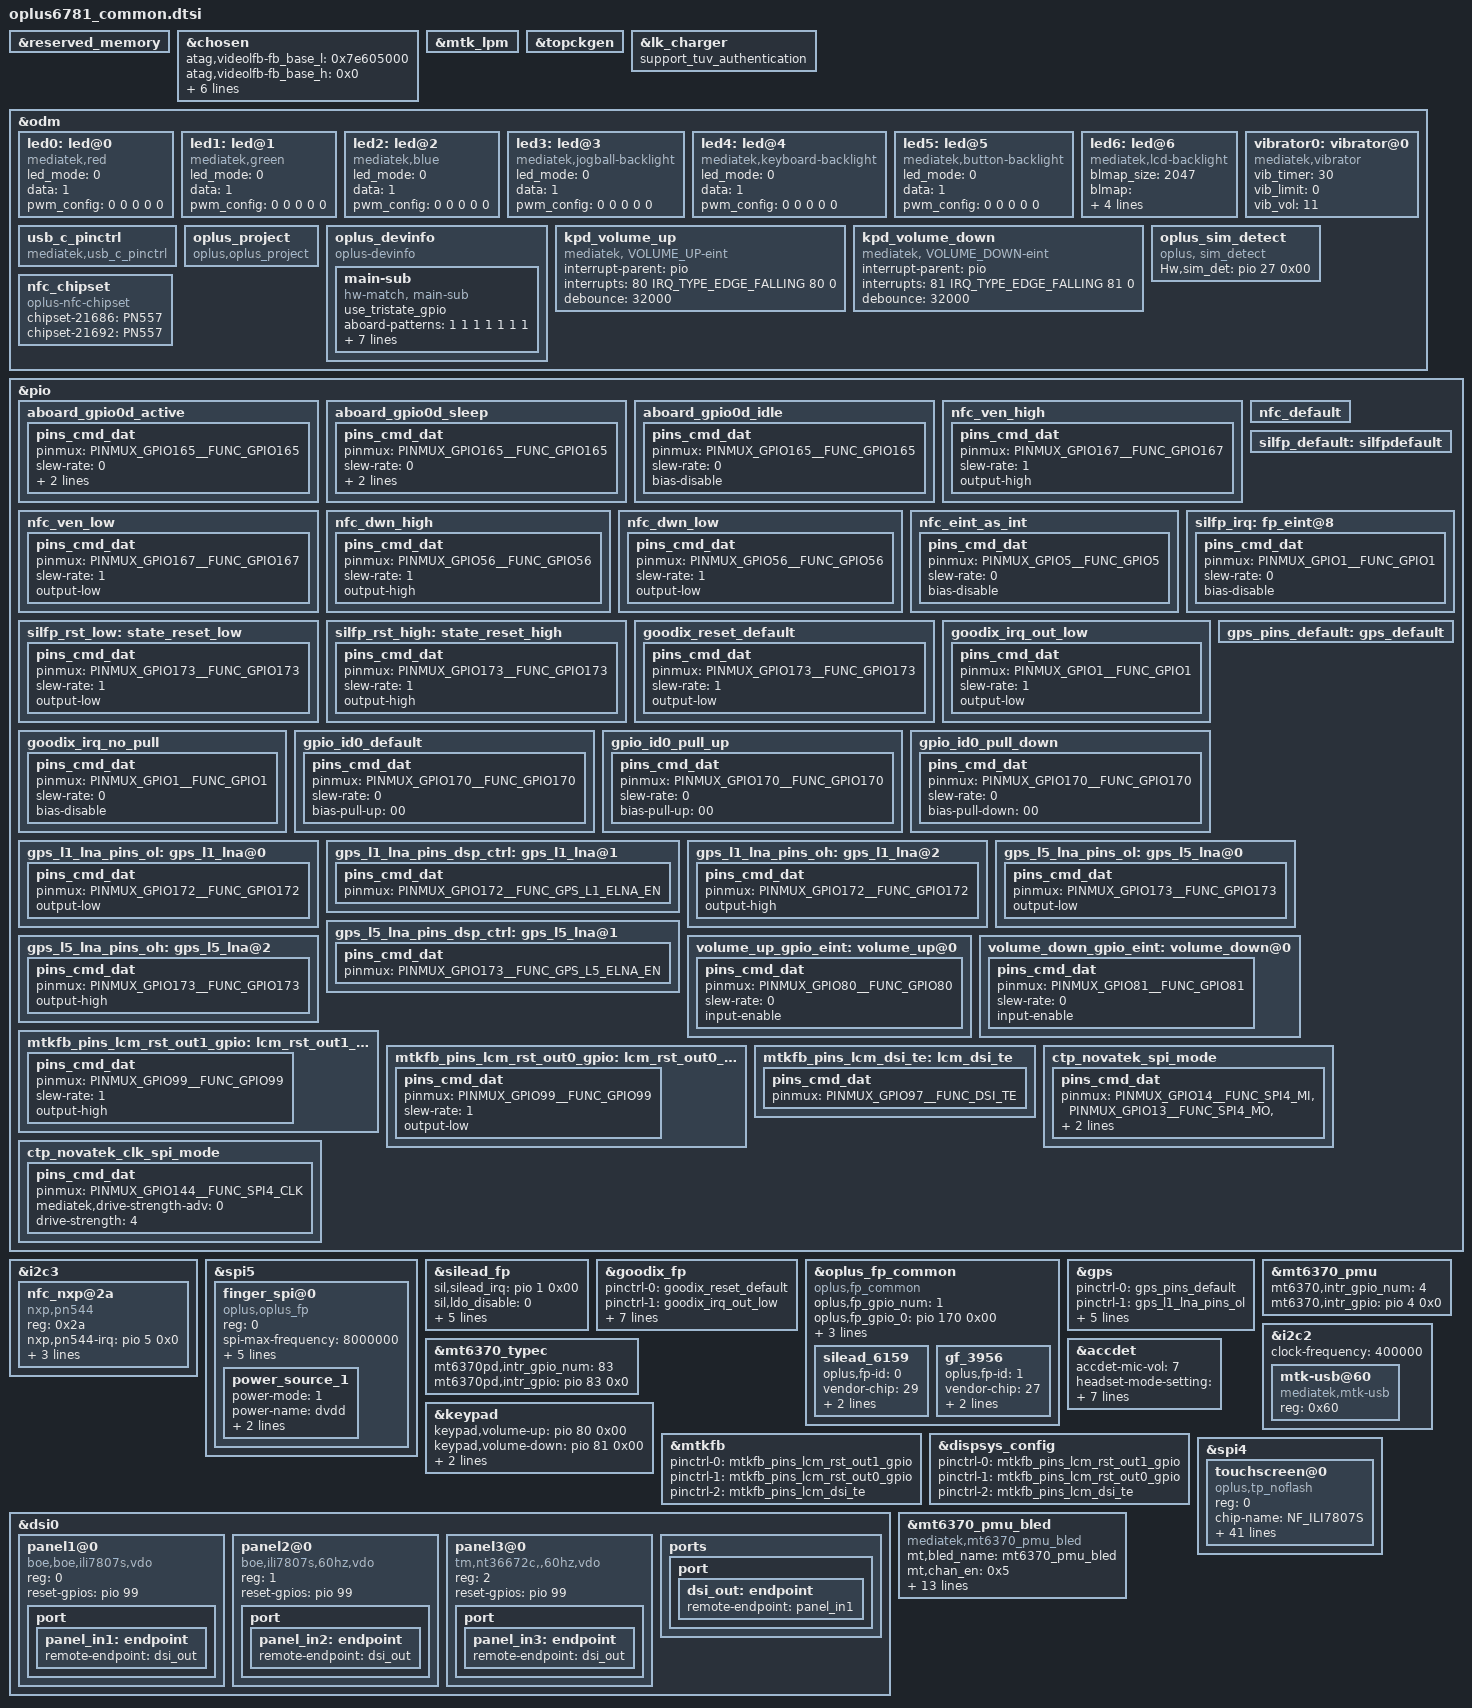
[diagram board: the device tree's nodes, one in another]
/*
 * Copyright (C) 2015 MediaTek Inc.
 *
 * This program is free software: you can redistribute it and/or modify
 * it under the terms of the GNU General Public License version 2 as
 * published by the Free Software Foundation.
 *
 * This program is distributed in the hope that it will be useful,
 * but WITHOUT ANY WARRANTY; without even the implied warranty of
 * MERCHANTABILITY or FITNESS FOR A PARTICULAR PURPOSE. See the
 * GNU General Public License for more details.
 */
#include <dt-bindings/interrupt-controller/irq.h>
#include <dt-bindings/interrupt-controller/arm-gic.h>
#include <dt-bindings/pinctrl/mt6781-pinfunc.h>

&reserved_memory {
};

/* chosen */
&chosen {
	/* fpga may has no lk, we need to specify display info here */
	/* fb buffer is reserved using this dts by memory node above */
	atag,videolfb-fb_base_l = <0x7e605000>;
	atag,videolfb-fb_base_h = <0x0>;
	atag,videolfb-islcmfound = <1>;
	atag,videolfb-islcm_inited = <0>;
	atag,videolfb-fps= <6000>;
	atag,videolfb-vramSize= <0x017e8000>;
	atag,videolfb-lcmname=
		"nt35695_fhd_dsi_cmd_truly_rt5081_drv";
};

&mtk_lpm {
};

&topckgen {
};

&lk_charger {
	support_tuv_authentication;
};

&odm {
	led0:led@0 {
		compatible = "mediatek,red";
		led_mode = <0>;
		data = <1>;
		pwm_config = <0 0 0 0 0>;
	};
	led1:led@1 {
		compatible = "mediatek,green";
		led_mode = <0>;
		data = <1>;
		pwm_config = <0 0 0 0 0>;
	};
	led2:led@2 {
		compatible = "mediatek,blue";
		led_mode = <0>;
		data = <1>;
		pwm_config = <0 0 0 0 0>;
	};
	led3:led@3 {
		compatible = "mediatek,jogball-backlight";
		led_mode = <0>;
		data = <1>;
		pwm_config = <0 0 0 0 0>;
	};
	led4:led@4 {
		compatible = "mediatek,keyboard-backlight";
		led_mode = <0>;
		data = <1>;
		pwm_config = <0 0 0 0 0>;
	};
	led5:led@5 {
		compatible = "mediatek,button-backlight";
		led_mode = <0>;
		data = <1>;
		pwm_config = <0 0 0 0 0>;
	};
	led6:led@6 {
		compatible = "mediatek,lcd-backlight";
		blmap_size = <2047>;
		blmap = <
			0 186 295 372 432 481 523 559
			590 618 644 667 689 709 727 745
			761 776 791 805 818 830 842 854
			865 875 885 895 904 914 922 931
			939 947 955 963 970 977 984 991
			997 1004 1010 1016 1022 1028 1034 1040
			1045 1051 1056 1061 1066 1071 1076 1081
			1086 1091 1095 1100 1104 1109 1113 1117
			1121 1125 1129 1133 1137 1141 1145 1149
			1152 1156 1160 1163 1167 1170 1174 1177
			1180 1184 1187 1190 1193 1196 1200 1203
			1206 1209 1212 1215 1217 1220 1223 1226
			1229 1232 1234 1237 1240 1242 1245 1247
			1250 1253 1255 1258 1260 1263 1265 1267
			1270 1272 1275 1277 1279 1281 1284 1286
			1288 1290 1293 1295 1297 1299 1301 1303
			1305 1307 1309 1312 1314 1316 1318 1320
			1322 1323 1325 1327 1329 1331 1333 1335
			1337 1339 1340 1342 1344 1346 1348 1349
			1351 1353 1355 1356 1358 1360 1362 1363
			1365 1367 1368 1370 1371 1373 1375 1376
			1378 1379 1381 1383 1384 1386 1387 1389
			1390 1392 1393 1395 1396 1398 1399 1401
			1402 1404 1405 1407 1408 1409 1411 1412
			1414 1415 1416 1418 1419 1420 1422 1423
			1424 1426 1427 1428 1430 1431 1432 1434
			1435 1436 1438 1439 1440 1441 1443 1444
			1445 1446 1448 1449 1450 1451 1452 1454
			1455 1456 1457 1458 1460 1461 1462 1463
			1464 1465 1466 1468 1469 1470 1471 1472
			1473 1474 1475 1477 1478 1479 1480 1481
			1482 1483 1484 1485 1486 1487 1488 1489
			1491 1492 1493 1494 1495 1496 1497 1498
			1499 1500 1501 1502 1503 1504 1505 1506
			1507 1508 1509 1510 1511 1512 1513 1514
			1514 1515 1516 1517 1518 1519 1520 1521
			1522 1523 1524 1525 1526 1527 1528 1528
			1529 1530 1531 1532 1533 1534 1535 1536
			1536 1537 1538 1539 1540 1541 1542 1543
			1543 1544 1545 1546 1547 1548 1549 1549
			1550 1551 1552 1553 1554 1554 1555 1556
			1557 1558 1558 1559 1560 1561 1562 1562
			1563 1564 1565 1566 1566 1567 1568 1569
			1570 1570 1571 1572 1573 1573 1574 1575
			1576 1577 1577 1578 1579 1580 1580 1581
			1582 1583 1583 1584 1585 1585 1586 1587
			1588 1588 1589 1590 1591 1591 1592 1593
			1593 1594 1595 1596 1596 1597 1598 1598
			1599 1600 1600 1601 1602 1603 1603 1604
			1605 1605 1606 1607 1607 1608 1609 1609
			1610 1611 1611 1612 1613 1613 1614 1615
			1615 1616 1617 1617 1618 1619 1619 1620
			1621 1621 1622 1622 1623 1624 1624 1625
			1626 1626 1627 1628 1628 1629 1629 1630
			1631 1631 1632 1632 1633 1634 1634 1635
			1636 1636 1637 1637 1638 1639 1639 1640
			1640 1641 1642 1642 1643 1643 1644 1645
			1645 1646 1646 1647 1647 1648 1649 1649
			1650 1650 1651 1652 1652 1653 1653 1654
			1654 1655 1655 1656 1657 1657 1658 1658
			1659 1659 1660 1661 1661 1662 1662 1663
			1663 1664 1664 1665 1665 1666 1667 1667
			1668 1668 1669 1669 1670 1670 1671 1671
			1672 1672 1673 1674 1674 1675 1675 1676
			1676 1677 1677 1678 1678 1679 1679 1680
			1680 1681 1681 1682 1682 1683 1683 1684
			1684 1685 1685 1686 1686 1687 1687 1688
			1688 1689 1689 1690 1690 1691 1691 1692
			1692 1693 1693 1694 1694 1695 1695 1696
			1696 1697 1697 1698 1698 1699 1699 1700
			1700 1701 1701 1702 1702 1703 1703 1704
			1704 1704 1705 1705 1706 1706 1707 1707
			1708 1708 1709 1709 1710 1710 1711 1711
			1711 1712 1712 1713 1713 1714 1714 1715
			1715 1716 1716 1716 1717 1717 1718 1718
			1719 1719 1720 1720 1720 1721 1721 1722
			1722 1723 1723 1724 1724 1724 1725 1725
			1726 1726 1727 1727 1727 1728 1728 1729
			1729 1730 1730 1730 1731 1731 1732 1732
			1733 1733 1733 1734 1734 1735 1735 1736
			1736 1736 1737 1737 1738 1738 1738 1739
			1739 1740 1740 1741 1741 1741 1742 1742
			1743 1743 1743 1744 1744 1745 1745 1745
			1746 1746 1747 1747 1747 1748 1748 1749
			1749 1749 1750 1750 1751 1751 1751 1752
			1752 1753 1753 1753 1754 1754 1755 1755
			1755 1756 1756 1757 1757 1757 1758 1758
			1758 1759 1759 1760 1760 1760 1761 1761
			1762 1762 1762 1763 1763 1763 1764 1764
			1765 1765 1765 1766 1766 1766 1767 1767
			1768 1768 1768 1769 1769 1769 1770 1770
			1771 1771 1771 1772 1772 1772 1773 1773
			1773 1774 1774 1775 1775 1775 1776 1776
			1776 1777 1777 1777 1778 1778 1779 1779
			1779 1780 1780 1780 1781 1781 1781 1782
			1782 1782 1783 1783 1783 1784 1784 1785
			1785 1785 1786 1786 1786 1787 1787 1787
			1788 1788 1788 1789 1789 1789 1790 1790
			1790 1791 1791 1791 1792 1792 1792 1793
			1793 1793 1794 1794 1795 1795 1795 1796
			1796 1796 1797 1797 1797 1798 1798 1798
			1799 1799 1799 1800 1800 1800 1800 1801
			1801 1801 1802 1802 1802 1803 1803 1803
			1804 1804 1804 1805 1805 1805 1806 1806
			1806 1807 1807 1807 1808 1808 1808 1809
			1809 1809 1810 1810 1810 1811 1811 1811
			1811 1812 1812 1812 1813 1813 1813 1814
			1814 1814 1815 1815 1815 1816 1816 1816
			1816 1817 1817 1817 1818 1818 1818 1819
			1819 1819 1820 1820 1820 1820 1821 1821
			1821 1822 1822 1822 1823 1823 1823 1824
			1824 1824 1824 1825 1825 1825 1826 1826
			1826 1827 1827 1827 1827 1828 1828 1828
			1829 1829 1829 1830 1830 1830 1830 1831
			1831 1831 1832 1832 1832 1832 1833 1833
			1833 1834 1834 1834 1835 1835 1835 1835
			1836 1836 1836 1837 1837 1837 1837 1838
			1838 1838 1839 1839 1839 1839 1840 1840
			1840 1841 1841 1841 1841 1842 1842 1842
			1843 1843 1843 1843 1844 1844 1844 1844
			1845 1845 1845 1846 1846 1846 1846 1847
			1847 1847 1848 1848 1848 1848 1849 1849
			1849 1849 1850 1850 1850 1851 1851 1851
			1851 1852 1852 1852 1852 1853 1853 1853
			1854 1854 1854 1854 1855 1855 1855 1855
			1856 1856 1856 1857 1857 1857 1857 1858
			1858 1858 1858 1859 1859 1859 1859 1860
			1860 1860 1861 1861 1861 1861 1862 1862
			1862 1862 1863 1863 1863 1863 1864 1864
			1864 1864 1865 1865 1865 1865 1866 1866
			1866 1866 1867 1867 1867 1868 1868 1868
			1868 1869 1869 1869 1869 1870 1870 1870
			1870 1871 1871 1871 1871 1872 1872 1872
			1872 1873 1873 1873 1873 1874 1874 1874
			1874 1875 1875 1875 1875 1876 1876 1876
			1876 1877 1877 1877 1877 1878 1878 1878
			1878 1879 1879 1879 1879 1880 1880 1880
			1880 1881 1881 1881 1881 1882 1882 1882
			1882 1883 1883 1883 1883 1883 1884 1884
			1884 1884 1885 1885 1885 1885 1886 1886
			1886 1886 1887 1887 1887 1887 1888 1888
			1888 1888 1889 1889 1889 1889 1889 1890
			1890 1890 1890 1891 1891 1891 1891 1892
			1892 1892 1892 1893 1893 1893 1893 1893
			1894 1894 1894 1894 1895 1895 1895 1895
			1896 1896 1896 1896 1896 1897 1897 1897
			1897 1898 1898 1898 1898 1899 1899 1899
			1899 1899 1900 1900 1900 1900 1901 1901
			1901 1901 1901 1902 1902 1902 1902 1903
			1903 1903 1903 1904 1904 1904 1904 1904
			1905 1905 1905 1905 1906 1906 1906 1906
			1906 1907 1907 1907 1907 1908 1908 1908
			1908 1908 1909 1909 1909 1909 1910 1910
			1910 1910 1910 1911 1911 1911 1911 1911
			1912 1912 1912 1912 1913 1913 1913 1913
			1913 1914 1914 1914 1914 1915 1915 1915
			1915 1915 1916 1916 1916 1916 1916 1917
			1917 1917 1917 1918 1918 1918 1918 1918
			1919 1919 1919 1919 1919 1920 1920 1920
			1920 1920 1921 1921 1921 1921 1922 1922
			1922 1922 1922 1923 1923 1923 1923 1923
			1924 1924 1924 1924 1924 1925 1925 1925
			1925 1926 1926 1926 1926 1926 1927 1927
			1927 1927 1927 1928 1928 1928 1928 1928
			1929 1929 1929 1929 1929 1930 1930 1930
			1930 1930 1931 1931 1931 1931 1931 1932
			1932 1932 1932 1932 1933 1933 1933 1933
			1933 1934 1934 1934 1934 1934 1935 1935
			1935 1935 1935 1936 1936 1936 1936 1936
			1937 1937 1937 1937 1937 1938 1938 1938
			1938 1938 1939 1939 1939 1939 1939 1940
			1940 1940 1940 1940 1941 1941 1941 1941
			1941 1942 1942 1942 1942 1942 1943 1943
			1943 1943 1943 1944 1944 1944 1944 1944
			1944 1945 1945 1945 1945 1945 1946 1946
			1946 1946 1946 1947 1947 1947 1947 1947
			1948 1948 1948 1948 1948 1948 1949 1949
			1949 1949 1949 1950 1950 1950 1950 1950
			1951 1951 1951 1951 1951 1952 1952 1952
			1952 1952 1952 1953 1953 1953 1953 1953
			1954 1954 1954 1954 1954 1955 1955 1955
			1955 1955 1955 1956 1956 1956 1956 1956
			1957 1957 1957 1957 1957 1957 1958 1958
			1958 1958 1958 1959 1959 1959 1959 1959
			1959 1960 1960 1960 1960 1960 1961 1961
			1961 1961 1961 1961 1962 1962 1962 1962
			1962 1963 1963 1963 1963 1963 1963 1964
			1964 1964 1964 1964 1965 1965 1965 1965
			1965 1965 1966 1966 1966 1966 1966 1966
			1967 1967 1967 1967 1967 1968 1968 1968
			1968 1968 1968 1969 1969 1969 1969 1969
			1970 1970 1970 1970 1970 1970 1971 1971
			1971 1971 1971 1971 1972 1972 1972 1972
			1972 1972 1973 1973 1973 1973 1973 1974
			1974 1974 1974 1974 1974 1975 1975 1975
			1975 1975 1975 1976 1976 1976 1976 1976
			1976 1977 1977 1977 1977 1977 1977 1978
			1978 1978 1978 1978 1978 1979 1979 1979
			1979 1979 1980 1980 1980 1980 1980 1980
			1981 1981 1981 1981 1981 1981 1982 1982
			1982 1982 1982 1982 1983 1983 1983 1983
			1983 1983 1984 1984 1984 1984 1984 1984
			1985 1985 1985 1985 1985 1985 1986 1986
			1986 1986 1986 1986 1987 1987 1987 1987
			1987 1987 1988 1988 1988 1988 1988 1988
			1988 1989 1989 1989 1989 1989 1989 1990
			1990 1990 1990 1990 1990 1991 1991 1991
			1991 1991 1991 1992 1992 1992 1992 1992
			1992 1993 1993 1993 1993 1993 1993 1994
			1994 1994 1994 1994 1994 1994 1995 1995
			1995 1995 1995 1995 1996 1996 1996 1996
			1996 1996 1997 1997 1997 1997 1997 1997
			1998 1998 1998 1998 1998 1998 1998 1999
			1999 1999 1999 1999 1999 2000 2000 2000
			2000 2000 2000 2000 2001 2001 2001 2001
			2001 2001 2002 2002 2002 2002 2002 2002
			2003 2003 2003 2003 2003 2003 2003 2004
			2004 2004 2004 2004 2004 2005 2005 2005
			2005 2005 2005 2005 2006 2006 2006 2006
			2006 2006 2007 2007 2007 2007 2007 2007
			2007 2008 2008 2008 2008 2008 2008 2009
			2009 2009 2009 2009 2009 2009 2010 2010
			2010 2010 2010 2010 2010 2011 2011 2011
			2011 2011 2011 2012 2012 2012 2012 2012
			2012 2012 2013 2013 2013 2013 2013 2013
			2013 2014 2014 2014 2014 2014 2014 2015
			2015 2015 2015 2015 2015 2015 2016 2016
			2016 2016 2016 2016 2016 2017 2017 2017
			2017 2017 2017 2017 2018 2018 2018 2018
			2018 2018 2019 2019 2019 2019 2019 2019
			2019 2020 2020 2020 2020 2020 2020 2020
			2021 2021 2021 2021 2021 2021 2021 2022
			2022 2022 2022 2022 2022 2022 2023 2023
			2023 2023 2023 2023 2023 2024 2024 2024
			2024 2024 2024 2024 2025 2025 2025 2025
			2025 2025 2025 2026 2026 2026 2026 2026
			2026 2026 2027 2027 2027 2027 2027 2027
			2027 2028 2028 2028 2028 2028 2028 2028
			2029 2029 2029 2029 2029 2029 2029 2030
			2030 2030 2030 2030 2030 2030 2031 2031
			2031 2031 2031 2031 2031 2032 2032 2032
			2032 2032 2032 2032 2032 2033 2033 2033
			2033 2033 2033 2033 2034 2034 2034 2034
			2034 2034 2034 2035 2035 2035 2035 2035
			2035 2035 2036 2036 2036 2036 2036 2036
			2036 2036 2037 2037 2037 2037 2037 2037
			2037 2038 2038 2038 2038 2038 2038 2038
			2039 2039 2039 2039 2039 2039 2039 2039
			2040 2040 2040 2040 2040 2040 2040 2041
			2041 2041 2041 2041 2041 2041 2041 2042
			2042 2042 2042 2042 2042 2042 2043 2043
			2043 2043 2043 2043 2043 2044 2044 2044
			2044 2044 2044 2044 2044 2045 2045 2045
			2045 2045 2045 2045 2045 2046 2046 2046
			2046 2046 2046 2046 2047 2047 2047 2047
			2047 2047 2047 2047 2047 2047 2047
		>;
/* #ifdef OPLUS_BUG_COMPATIBILITY */
		led_mode = <6>;
/* #endif */
		data = <1>;
		pwm_config = <0 1 0 0 0>;
	};
	vibrator0:vibrator@0 {
		compatible = "mediatek,vibrator";
		/*vib_timer = <25>;
		vib_limit = <9>;
		vib_vol= <9>;*/
		vib_timer = <30>;
		vib_limit = <0>;
		vib_vol= <11>;
	};

	usb_c_pinctrl:usb_c_pinctrl {
		compatible = "mediatek,usb_c_pinctrl";
	};

	oplus_project:oplus_project {
		compatible = "oplus,oplus_project";
	};
	oplus_devinfo:oplus_devinfo {
		compatible = "oplus-devinfo";

		main-sub {
			compatible = "hw-match, main-sub";
			use_tristate_gpio;
			aboard-patterns = <1 1 1 1 1 1 1>;
			aboard-patterns-evt2 = <1 1 1 1 1 2 2>;
			/*main board*/
			match-projects = <21684 21685 21686 21687 21690 21691 21692>;
			aboard-gpio0 = <&pio 165 0x0>;
			pinctrl-names = "aboard_gpio0d_active", "aboard_gpio0d_sleep", "aboard_gpio0d_idle";
			pinctrl-0 = <&aboard_gpio0d_active>;
			pinctrl-1 = <&aboard_gpio0d_sleep>;
			pinctrl-2 = <&aboard_gpio0d_idle>;
		};
	};

	kpd_volume_up:kpd_volume_up {
               compatible = "mediatek, VOLUME_UP-eint";
               interrupt-parent = <&pio>;
               interrupts = <80 IRQ_TYPE_EDGE_FALLING 80 0>;
               debounce = <32000>;
               status = "okay";
       };

	kpd_volume_down:kpd_volume_down {
			compatible = "mediatek, VOLUME_DOWN-eint";
			interrupt-parent = <&pio>;
			interrupts = <81 IRQ_TYPE_EDGE_FALLING 81 0>;
			debounce = <32000>;
			status = "okay";
	};

	//#ifdef OPLUS_FEATURE_TP_BASIC
		oplus_sim_detect {
			compatible = "oplus, sim_detect";
			Hw,sim_det = <&pio 27 0x00>;
		};
	//#endif /* OPLUS_FEATURE_TP_BASIC */

//#ifdef OPLUS_FEATURE_NFC_BRINGUP
    nfc_chipset:nfc_chipset {
        compatible = "oplus-nfc-chipset";
        chipset-21686 = "PN557";
        chipset-21692 = "PN557";
    };
//#endif /* OPLUS_FEATURE_NFC_BRINGUP */
};

&pio {
	aboard_gpio0d_active: aboard_gpio0d_active {
		pins_cmd_dat {
			pinmux = <PINMUX_GPIO165__FUNC_GPIO165>;
			slew-rate = <0>;
			bias-pull-up = <01>;
			input-enable;
		};
	};
	aboard_gpio0d_sleep: aboard_gpio0d_sleep {
		pins_cmd_dat {
			pinmux = <PINMUX_GPIO165__FUNC_GPIO165>;
			slew-rate = <0>;
			bias-pull-up = <00>;
			input-enable;
		};
	};
	aboard_gpio0d_idle: aboard_gpio0d_idle {
		pins_cmd_dat {
			pinmux = <PINMUX_GPIO165__FUNC_GPIO165>;
			slew-rate = <0>;
			bias-disable;
		};
	};
};

//#ifdef OPLUS_FEATURE_NFC_BRINGUP
/* NFC GPIO standardization start */
&pio {
    nfc_ven_high: nfc_ven_high {
                pins_cmd_dat {
                        pinmux = <PINMUX_GPIO167__FUNC_GPIO167>;
                        slew-rate = <1>;
                        output-high;
                };
        };
        nfc_ven_low: nfc_ven_low {
                pins_cmd_dat {
                        pinmux = <PINMUX_GPIO167__FUNC_GPIO167>;
                        slew-rate = <1>;
                        output-low;
                };
        };
        nfc_dwn_high: nfc_dwn_high {
                pins_cmd_dat {
                        pinmux = <PINMUX_GPIO56__FUNC_GPIO56>;
                        slew-rate = <1>;
                        output-high;
                };
        };
        nfc_dwn_low: nfc_dwn_low {
                pins_cmd_dat {
                        pinmux = <PINMUX_GPIO56__FUNC_GPIO56>;
                        slew-rate = <1>;
                        output-low;
                };
       };
        nfc_eint_as_int: nfc_eint_as_int {
          pins_cmd_dat {
                        pinmux = <PINMUX_GPIO5__FUNC_GPIO5>;
                        slew-rate = <0>;
                       bias-disable;
                };
        };
        nfc_default: nfc_default {
        };
};

&i2c3 {
       status = "okay";
       nfc_nxp@2a {
               compatible = "nxp,pn544";
               reg = <0x2a>;
               nxp,pn544-irq = <&pio 5 0x0>;
               nxp,pn544-ven = <&pio 167 0x0>;
               nxp,pn544-fw-dwnld = <&pio 56 0x0>;
               interrupt-parent = <&pio>;
       };
};
/* NFC GPIO standardization end */
//#endif /* OPLUS_FEATURE_NFC_BRINGUP */

&spi5 {
	#address-cells = <1>;
	#size-cells = <0>;
	status = "okay";
	finger_spi@0 {
	    compatible = "oplus,oplus_fp";
	    reg = <0>;
	    spi-max-frequency = <8000000>;
	    netlink-event = <30>;
	    spi-id = <1>;
	    spi-irq = <1>;
	    spi-reg = <0x11015000>;
	    dvdd-config = <3000000 3000000 150000>;
        status = "okay";
        power_source_1{
            power-mode = <1>;
            power-name = "dvdd";
            power-config = "dvdd-config";
            delay-time = <0>;
};
    };
};
/*-------------------the silead device config start----------------------*/
&pio {
	silfp_default: silfpdefault {
	};
	silfp_rst_low: state_reset_low {
		pins_cmd_dat {
			pinmux = <PINMUX_GPIO173__FUNC_GPIO173>;
			slew-rate = <1>;
			output-low;
		};
	};
	silfp_rst_high: state_reset_high {
		pins_cmd_dat {
			pinmux = <PINMUX_GPIO173__FUNC_GPIO173>;
			slew-rate = <1>;
			output-high;
		};
	};
	silfp_irq: fp_eint@8 {
		pins_cmd_dat {
			pinmux = <PINMUX_GPIO1__FUNC_GPIO1>;
			slew-rate = <0>;
			bias-disable;
		};
	};
};
&silead_fp {
	sil,silead_irq = <&pio 1 0x00>;
	sil,ldo_disable = <0>;
	vmch_enable = <2>;
	pinctrl-names = "default", "rst-low", "rst-high",
	                "irq-init";
	pinctrl-0 = <&silfp_default>;
	pinctrl-1 = <&silfp_rst_low>;
	pinctrl-2 = <&silfp_rst_high>;
	pinctrl-3 = <&silfp_irq>;
	status = "okay";
};
/*-------------------the silead device config end----------------------*/

&pio {
	goodix_reset_default: goodix_reset_default {
		pins_cmd_dat {
			pinmux = <PINMUX_GPIO173__FUNC_GPIO173>;
			slew-rate = <1>;
			output-low;
		};
	};
	goodix_irq_out_low: goodix_irq_out_low {
		pins_cmd_dat {
			pinmux = <PINMUX_GPIO1__FUNC_GPIO1>;
			slew-rate = <1>;
			output-low;
		};
	};
	goodix_irq_no_pull: goodix_irq_no_pull {
		pins_cmd_dat {
			pinmux = <PINMUX_GPIO1__FUNC_GPIO1>;
			slew-rate = <0>;
			bias-disable;
		};
	};
};

&goodix_fp {
	pinctrl-names = "goodix_reset_default", "goodix_irq_out_low", "goodix_irq_no_pull";
	pinctrl-0 = <&goodix_reset_default>;
	pinctrl-1 = <&goodix_irq_out_low>;
	pinctrl-2 = <&goodix_irq_no_pull>;
	interrupt-parent = <&pio>;
	interrupts = <1 0>;
	goodix,gpio_irq = <&pio 1 0x00>;
	goodix,gpio_reset = <&pio 173 0x00>;
	gf,cs_gpio_disable = <1>;
	spi-max-frequency = <8000000>;
	status = "okay";
};

/*the finger_id config to project dts.*/

&pio{
	gpio_id0_default: gpio_id0_default {
		pins_cmd_dat {
			pinmux = <PINMUX_GPIO170__FUNC_GPIO170>;
			slew-rate = <0>;
			bias-pull-up = <00>;
		};
	};
	gpio_id0_pull_up: gpio_id0_pull_up {
		pins_cmd_dat {
			pinmux = <PINMUX_GPIO170__FUNC_GPIO170>;
			slew-rate = <0>;
			bias-pull-up = <00>;
		};
	};
	gpio_id0_pull_down: gpio_id0_pull_down {
		pins_cmd_dat {
			pinmux = <PINMUX_GPIO170__FUNC_GPIO170>;
			slew-rate = <0>;
			bias-pull-down = <00>;
		};
	};
};

&oplus_fp_common {
	compatible = "oplus,fp_common"; //Manufacture, and Model
	oplus,fp_gpio_num = <1>;
	oplus,fp_gpio_0 = <&pio 170 0x00>;
	pinctrl-names = "gpio_id0_default", "gpio_id0_pull_up", "gpio_id0_pull_down";
	pinctrl-0 = <&gpio_id0_default>;
	pinctrl-1 = <&gpio_id0_pull_up>;
	pinctrl-2 = <&gpio_id0_pull_down>;

    silead_6159 {
            oplus,fp-id = <0>; /* fp id mapping table */
            vendor-chip = <29>; /* please refer to the struct fp_vendor_t in oppo_fp_commmon.n */
            eng-menu = "-1,-1"; /* represents SNR, inclination test item in engineer menu, and 0/1 means off/on */
            chip-name = "S_gsl6159";  /* /proc/fp_id, will be displayed in engineer menu  */
    };
    gf_3956 {
            oplus,fp-id = <1>; /* fp id mapping table */
            vendor-chip = <27>; /* please refer to the struct fp_vendor_t in oppo_fp_commmon.n */
            eng-menu = "-1,-1"; /* represents SNR, inclination test item in engineer menu, and 0/1 means off/on */
            chip-name = "G_3956";  /* /proc/fp_id, will be displayed in engineer menu  */
    };
};

/* GPS GPIO standardization start */
&pio {
	gps_pins_default: gps_default {
	};

	gps_l1_lna_pins_ol: gps_l1_lna@0 {
		pins_cmd_dat {
			pinmux = <PINMUX_GPIO172__FUNC_GPIO172>;
			output-low;
		};
	};
	gps_l1_lna_pins_dsp_ctrl: gps_l1_lna@1 {
		pins_cmd_dat {
			pinmux = <PINMUX_GPIO172__FUNC_GPS_L1_ELNA_EN>;
		};
	};
	gps_l1_lna_pins_oh: gps_l1_lna@2 {
		pins_cmd_dat {
			pinmux = <PINMUX_GPIO172__FUNC_GPIO172>;
			output-high;
		};
	};

	gps_l5_lna_pins_ol: gps_l5_lna@0 {
		pins_cmd_dat {
			pinmux = <PINMUX_GPIO173__FUNC_GPIO173>;
			output-low;
		};
	};
	gps_l5_lna_pins_dsp_ctrl: gps_l5_lna@1 {
		pins_cmd_dat {
			pinmux = <PINMUX_GPIO173__FUNC_GPS_L5_ELNA_EN>;
		};
	};
	gps_l5_lna_pins_oh: gps_l5_lna@2 {
		pins_cmd_dat {
			pinmux = <PINMUX_GPIO173__FUNC_GPIO173>;
			output-high;
		};
	};
};

&gps {
	pinctrl-names = "default",
		"gps_l1_lna_disable",
		"gps_l1_lna_dsp_ctrl",
		"gps_l1_lna_enable",
		"gps_l5_lna_disable",
		"gps_l5_lna_dsp_ctrl",
		"gps_l5_lna_enable";
	pinctrl-0 = <&gps_pins_default>;
	pinctrl-1 = <&gps_l1_lna_pins_ol>;
	pinctrl-2 = <&gps_l1_lna_pins_dsp_ctrl>;
	pinctrl-3 = <&gps_l1_lna_pins_oh>;
	pinctrl-4 = <&gps_l5_lna_pins_ol>;
	pinctrl-5 = <&gps_l5_lna_pins_dsp_ctrl>;
	pinctrl-6 = <&gps_l5_lna_pins_oh>;
	status = "okay";
};
/* GPS GPIO standardization end */

&mt6370_pmu {
	mt6370,intr_gpio_num = <4>; /* direct defined GPIO num */
	mt6370,intr_gpio = <&pio 4 0x0>;
};

&mt6370_typec {
	mt6370pd,intr_gpio_num = <83>; /* direct defined GPIO num */
	mt6370pd,intr_gpio = <&pio 83 0x0>;
};

&i2c2 {
	clock-frequency = <400000>;
	mtk-usb@60 {
		compatible = "mediatek,mtk-usb";
		reg = <0x60>;
		status = "okay";
	};
};

&keypad {
	keypad,volume-up	= <&pio 80 0x00>;
	keypad,volume-down	= <&pio 81 0x00>;
	pinctrl-names = "volume_up_as_int", "volume_down_as_int";
	pinctrl-0 = <&volume_up_gpio_eint>;
	pinctrl-1 = <&volume_down_gpio_eint>;
	status = "okay";
};

&pio {
	volume_up_gpio_eint:volume_up@0{
		pins_cmd_dat {
			pinmux = <PINMUX_GPIO80__FUNC_GPIO80>;
			slew-rate = <0>;  /*direction 0:in, 1:out*/
			input-enable;
		};
	};
	volume_down_gpio_eint:volume_down@0{
		pins_cmd_dat {
			pinmux = <PINMUX_GPIO81__FUNC_GPIO81>;
			slew-rate = <0>;  /*direction 0:in, 1:out*/
			input-enable;
		};
	};
};

/* accdet start */
&accdet {
	/* accdet micbias voltage: 0x07,2.7v;0x05,2.5v;0x02,1.9v */
	accdet-mic-vol = <7>;
	headset-mode-setting = <0x500 0x500 1 0x1f0 0x800 0x800 0x20 0x44>;
	accdet-plugout-debounce = <1>;
	/*1:ACC mode, 2:low cost without in bias, 6:low cost with in bias*/
	accdet-mic-mode = <1>;
	/* eint_level_trigger: 8,LEVEL_LOW(DEF) ;4,LV_HIGH;others,LV_LOW */
	headset-eint-level-pol = <8>;
	/*0--MD_MAX--UP_MAX--DW_MAX*/
	headset-three-key-threshold = <0 80 220 400>;
	headset-three-key-threshold-CDD = <0 121 192 600>;
	/*0--MD_MAX--VOICE_MAX--UP_MAX--DW_MAX*/
	headset-four-key-threshold = <0 58 121 192 400>;
	status = "okay";
};
/* accdet end */

#ifndef CONFIG_FPGA_EARLY_PORTING
&pio {
	mtkfb_pins_lcm_rst_out1_gpio: lcm_rst_out1_gpio {
		pins_cmd_dat {
			pinmux = <PINMUX_GPIO99__FUNC_GPIO99>;
			slew-rate = <1>;
			output-high;
		};
	};

	mtkfb_pins_lcm_rst_out0_gpio: lcm_rst_out0_gpio {
		pins_cmd_dat {
			pinmux = <PINMUX_GPIO99__FUNC_GPIO99>;
			slew-rate = <1>;
			output-low;
		};
	};
	mtkfb_pins_lcm_dsi_te: lcm_dsi_te {
		pins_cmd_dat {
			pinmux = <PINMUX_GPIO97__FUNC_DSI_TE>;
		};
	};
};

&mtkfb {
	pinctrl-names = "lcm_rst_out1_gpio", "lcm_rst_out0_gpio",
		"mode_te_te";
	pinctrl-0 = <&mtkfb_pins_lcm_rst_out1_gpio>;
	pinctrl-1 = <&mtkfb_pins_lcm_rst_out0_gpio>;
	pinctrl-2 = <&mtkfb_pins_lcm_dsi_te>;
	status = "okay";
};

&dispsys_config {
	pinctrl-names =
		"lcm_rst_out1_gpio", "lcm_rst_out0_gpio",
		"mode_te_te";
	pinctrl-0 = <&mtkfb_pins_lcm_rst_out1_gpio>;
	pinctrl-1 = <&mtkfb_pins_lcm_rst_out0_gpio>;
	pinctrl-2 = <&mtkfb_pins_lcm_dsi_te>;
	status = "okay";
};

&dsi0 {
	status = "okay";
	#address-cells = <1>;
	#size-cells = <0>;
	panel1@0 {
		compatible = "boe,boe,ili7807s,vdo";
		reg = <0>;
		reset-gpios = <&pio 99 0>;
		pinctrl-names = "default";
		port {
			panel_in1: endpoint {
				remote-endpoint = <&dsi_out>;
			};
		};
	};
    panel2@0 {
		compatible = "boe,ili7807s,60hz,vdo";
		reg = <1>;
		reset-gpios = <&pio 99 0>;
		pinctrl-names = "default";
		port {
			panel_in2: endpoint {
				remote-endpoint = <&dsi_out>;
			};
		};
	};
    panel3@0 {
		compatible = "tm,nt36672c,,60hz,vdo";
		reg = <2>;
		reset-gpios = <&pio 99 0>;
		pinctrl-names = "default";
		port {
			panel_in3: endpoint {
				remote-endpoint = <&dsi_out>;
			};
		};
	};
	ports {
		port {
			dsi_out: endpoint {
				remote-endpoint = <&panel_in1>;
			};
		};
	};
};

#endif

/* TOUCH start */
&spi4 {
	status = "okay";

	 touchscreen@0 {
		compatible = "oplus,tp_noflash";
		reg = <0>; //Same as CS ID
		chip-name = "NF_ILI7807S";
		status = "okay";

		spi-max-frequency = <9600000>;
		interrupt-parent = <&pio>;
		interrupts = <12 IRQ_TYPE_EDGE_FALLING 12 0>;
		irq-gpio = <&pio 12 0x2002>;
		reset-gpio = <&pio 121 0>;

		platform_support_project = <21684 21685 21686 21687 21690 21691 21692>;
		platform_support_project_dir = <21684 21685 21686 21687 21690 21691 21692>;
		platform_support_project_commandline = "default_commandline","default_commandline","default_commandline","default_commandline","default_commandline","default_commandline","default_commandline";

		touchpanel,max-num-support = <10>;
		touchpanel,tx-rx-num = <18 36>;
		touchpanel,panel-coords = <1080 2412>;
		touchpanel,display-coords = <1080 2412>;
		touchpanel,touchmajor-limit = <0 54>;
		pinctrl-names = "default","pin_set_low", "pin_set_high";
		pinctrl-0 = <&ctp_novatek_spi_mode>, <&ctp_novatek_clk_spi_mode>;

		prevention,dead_area_width = <20 20>;
		prevention,condition_area_width = <60 60 160 160>;
		prevention,eli_area_width = <240 1000 1200 240>;

		incell_screen;
		irq_need_dev_resume_ok;
		fw_edge_limit_support;
		black_gesture_support;
		black_gesture_indep_support;
		charger_pump_support;
		headset_pump_support;
		esd_handle_support;
		black_gesture_test_support;
		game_switch_support;
		noflash_support;
		lcd_trigger_load_tp_fw_support;
		smart_gesture_support;
		pressure_report_support;
		fw_update_app_support;
		health_monitor_v2_support;
		touchpanel,button-type = <4>;
	};
};

&pio {
	ctp_novatek_spi_mode:ctp_novatek_spi_mode{
		pins_cmd_dat {
			pinmux = <PINMUX_GPIO14__FUNC_SPI4_MI>,
				<PINMUX_GPIO13__FUNC_SPI4_MO>,
				<PINMUX_GPIO145__FUNC_SPI4_CSB>;
			drive-strength = <4>;
		};
	};
	ctp_novatek_clk_spi_mode:ctp_novatek_clk_spi_mode{
                pins_cmd_dat {
                        pinmux = <PINMUX_GPIO144__FUNC_SPI4_CLK>;
			mediatek,drive-strength-adv = <0>;/*EH[2:0]*/
                        drive-strength = <4>;
                };
        };
};

&mt6370_pmu_bled {
	compatible = "mediatek,mt6370_pmu_bled";
	interrupt-names = "bled_ocp";
	mt,bled_name = "mt6370_pmu_bled";
	/* mt,ext_en_pin; */
	/* #ifdef OPLUS_BUG_COMPATIBILITY */
	mt,chan_en  = <0x5>; /* bit 0 1 2 3 -> chan 1 2 3 4 */
	/* #endif */
	mt,map_linear;
	mt,bl_ovp_level = <3>;	/* 0: 17v */
	/* 1: 21v */
	/* 2: 25v */
	/* 3: 29v */
	/* #ifdef OPLUS_BUG_COMPATIBILITY */
	mt,bl_ocp_level = <3>;	/* 0: 900mA */
	/* #endif */
	mt,pwm_fsample = <2>;	/* 0: 1MHz */
	/* 1: 4MHz */
	/* 2: or 3: 24mHz */
	mt,pwm_deglitch = <1>;	/* 0: no filter */
	/* 1: 100ns */
	/* 2: 160ns */
	/* 3: 200ns */
	mt,pwm_hys_en = <1>;	/* PWM Input Hysteresis */
	/* #ifdef OPLUS_BUG_COMPATIBILITY */
	mt,pwm_hys = <0>;	/* 0: 1 bit, 1: 2 bit */
	/* #endif */
	/* 2: 4 bit, 3: 6 bit */
	mt,pwm_avg_cycle = <0>; /* 0 disable avg, 1 avg 2 cycle, 2 avg 4 cycle */
	/* 3 avg 8 cycle, 4 avg 16 cycle, 5 avg 32 cycle */
	mt,bled_ramptime = <9>; /* 0, 500us, 750us, 1ms, 2ms, 5ms, 10ms, 20ms */
	/* 50ms, 100ms, 250ms, 800ms, 1s, 2s, 4s, 8s */
	mt,bled_flash_ramp = <1>; /* 0, 500us, 750us, 1ms, 2ms, 5ms */
	/* #ifdef OPLUS_BUG_COMPATIBILITY */
	mt,max_bled_brightness = <1878>; /* we have 11 bit resolution, quantize in driver */
	/* #endif */
	/* maximum 2047 */
	mt,bled_curr_scale = <0>;	/* 0: 30mA, 1: 22.5mA */
	/* 2: 20mA, 3: 17.5mA */
	/* If use bled lpf,
	 * Set	//mt,map_linear;
	 *	pwm_lpf_coef = <2>;
	 *	mt,pwm_lpf_en;
	 *	mt,bled_curr_mode;
	 * Else
	 * Set	mt,map_linear;
	 *	pwm_lpf_coef = <0>;
	 *	//mt,pwm_lpf_en;
	 *	//mt,bled_curr_mode;
	 */
	mt,pwm_lpf_coef = <0>;	/* 0: (1)/(2^15) */
	/* 1: (2)/(2^15) */
	/* 2: (3)/(2^15) */
	/* 3: (4)/(2^15) */
	/* with it, Alpha-LPF enable */
	/* mt,pwm_lpf_en; */
	/* with it, pwm duty is multiplied after
	 * linear/expenential mapper
	 */
	/* mt,bled_curr_mode; */
};

/*#include <oplus6781_21690/cust.dtsi>*/
/*#include <oplus6781_20684/cust.dtsi>*/
/*#include "mediatek/cust_mt6781_camera.dtsi"*/
#include "camera_ldo_mt6781.dtsi"
#include "mediatek/cust_mt6781_camera_space.dtsi"
//#include "mediatek/novatek-nt36xxx-space-spi.dtsi"
/*End of this file, DO NOT ADD ANYTHING HERE*/
